# RL6955_IP_SVD register map
Vendor: Realtek
Registers are 32-bit, read-write, reset 0x0 unless marked. A register's access mark holds for its fields unless they carry their own. Offsets are from the block's base; [hi:lo] are bit positions; {n}, {i} and the like mark numbered series.

## DVP_REG
Base 0x41805000
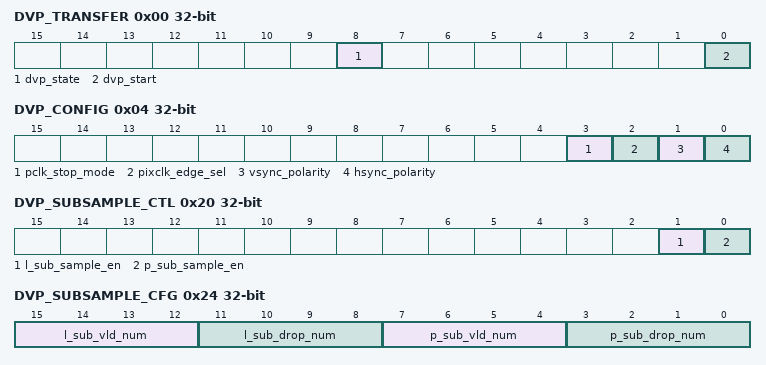
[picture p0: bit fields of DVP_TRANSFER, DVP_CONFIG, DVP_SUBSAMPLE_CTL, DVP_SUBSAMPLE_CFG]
0x00 DVP_TRANSFER access per field
  [8] dvp_state ro — 1: dvp enable 0: dvp disable
  [0] dvp_start wo — Start The transfer is launch if set this bit. When clear this bit, hardware will stop transfer after current image frame finish transfer. Dvp_start置1表示开流 停流方式可以选择配置immediate_stop或者是frame_stop来实现立即停流或者帧后停流.配置完immediate_stop或者是frame_stop后,dvp_state会自动拉低,拉低时间参考immediate_stop或者是frame_stop寄存器描述
0x04 DVP_CONFIG
  [3] pclk_stop_mode — PCLK Stop mode. Used when sensor uses HSYNC/VSYNC to perform gating on pclk, or pclk_stop_en open 0: normal 1: sensor pixclk stop mode
  [2] pixclk_edge_sel — Pixel clock sample edge. 0: falling edge, 1: rising edge.
  [1] vsync_polarity — Vsync polarity 0: active low, 1: active high.
  [0] hsync_polarity — Hsync polarity 0: active low, 1: active high.
0x0C DVP_CROP_START_X
  [12:0] dmy_pix_num — YUV path Unit: Bytes. This field indicates the number of dummy data before the valid data output. Hardware must bypass these dummy data and not sample the dummy data. yuv422 format config value is a multiple of 4 Eg: For YUV422 format, each pixel is represented by 2 bytes. Therefore, setting this field to 8 means skipping 4 pixels In formats like YUYV, YVYU, UYVY, and VYUY, data streams from the sensor to the DVP with each two pixels sharing the same UV components. Since each pair requires 2 pixels of 16bpp, it amounts to a total of 4 bytes. Therefore, operations involving this data should be done in multiples of 4 bytes. 用于crop丢掉数据
0x10 DVP_CROP_START_Y
  [11:0] dmy_line_num — YUV path This field indicates the number of dummy line before the valid line output. Hardware must bypass these dummy lines and not sample the dummy line data. 用于crop丢掉数据
0x14 DVP_WIDTH
  [12:0] pix_num_pre — YUV path Unit:bytes HORIZON_NUM10:0. This field indicates the number of valid data per line. yuv422 format config value is a multiple of 4 Eg: For YUV422 format, each pixel is represented by 2 bytes. Therefore, setting this field to 8 means reserved 4 pixels 用于crop选取有效数据,选取后的数据送往sub sample
0x18 DVP_HEIGHT
  [11:0] line_num_pre — YUV path VERTICAL_NUM10:0. This field indicates the number of valid line per frame. 用于crop选取有效数据,选取后的数据送往sub sample
0x1C DVP_FRAME_CNT ro
  [7:0] frame_num — Frame_cnt 7:0. This field is used to count the number of active Vsync from RealTimeImage transfer start. If the RealTimeImage transfer stop, the value of this register do not change. As soon as trigger RealTimeImage transfer, reset the value of thi register and restart to count.
0x20 DVP_SUBSAMPLE_CTL
  [1] l_sub_sample_en — YUV path Vertical (Line) Sub Sample control. 0: not sub sample, 1: sub sample.
  [0] p_sub_sample_en — YUV path Horizontal (Pixel) Sub sample control. 0: not sub sample, 1: sub sample.
0x24 DVP_SUBSAMPLE_CFG
  [15:12] l_sub_vld_num — YUV path Vertical Sub sample valid line number. 1-15:有效的line num是1-15 0:有效的line num是16
  [11:8] l_sub_drop_num — YUV path Vertical Sub sample invalid line number. 1-15:丢掉的line num是1-15 0:丢掉的line num是16
  [7:4] p_sub_vld_num — YUV path Horizontal (Pixel) Sub sample valid pixel number. yuv422 format config value: 4: vld 4 byte 8: vld 8 byte 12: vld 12 byte 0: vld 16 byte
  [3:0] p_sub_drop_num — YUV path Horizontal (Line) Sub sample invalid pixel number. yuv422 format config value: 4: drop 4 byte 8: drop 8 byte 12: drop 12 byte 0: drop 16 byte
0x28 DVP_FRMAE_VLD_CTL
  [3:0] frame_vld_num — FRAME_VALID_NUM 4'b0: all frame are valid otherwise: one frame valid in every (FRAME_VALID_NUM + 1 ) frames
0x2C DVP_YUV_TRANSFER
  [1:0] image_format — yuv422 sensor in format 2'b00: YUYV YUYV 2'b01: YVYU YVYU 2'b10: UYVY UYVY 2'b11: VYUY VYUY
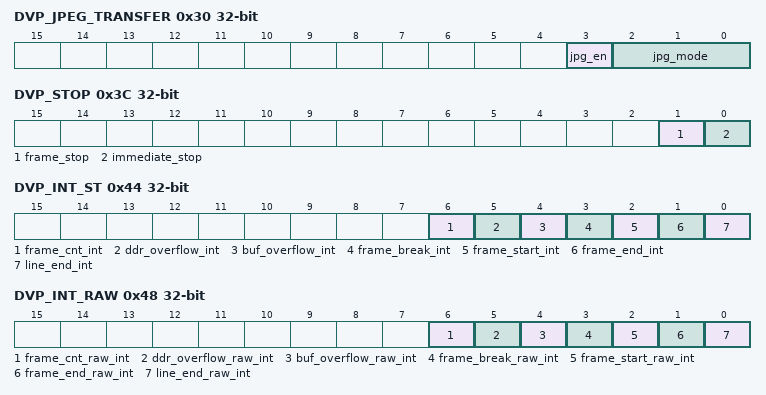
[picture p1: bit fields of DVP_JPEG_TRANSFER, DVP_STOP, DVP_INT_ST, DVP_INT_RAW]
0x30 DVP_JPEG_TRANSFER
  [3] jpg_en — DVP JPEG MODE EN 1: Enable DVP JPEG 0: Disable DVP JPEG
  [2:0] jpg_mode — DVP JPEG Mode 3'b000:Valid mode Use VSYNC as the frame synchronization signal and HSYNC as the horizontal synchronization signal. There is no dummy data in the frame. Support VSYNC pulse or level timing 3'b001:Frame mode Use VSYNC as the frame synchronization signal and HSYNC as the horizontal synchronization signal. There is dummy data in the frame. The frame contains valid data length , and valid data length is at the beginning of each line. 3'b010:Frame mode Use VSYNC as the frame synchronization signal and HSYNC as the horizontal synchronization signal. There is dummy data in the frame. The frame contains valid data length , and valid data length is at the end of each line. 3'b011:Frame mode Use VSYNC as the frame synchronization signal and HSYNC as the horizontal synchronization signal. There is dummy data in the frame. The frame does not contains valid data length. 3'b100:Use HSYNC as the frame synchronization signal,no dummy data
0x34 DVP_PCLK_GATING_CTL
  [0] pclk_gating_en — PCLK_GATING_EN 用于PCLK被VSYNC/HSYNC gating的情况,配合pclk_stop_mode使用,当pclk_gating_en置1时,pclk_stop_mode也要置1
0x38 DVP_PAD_CTL
  [1:0] pix_bit_swp — pixel bit switch 2'b01: pad[9:0]={bit7,bit6,bit5,bit4,bit3,bit2,bit1,bit0,2'd0} 2'b10: pad[9:0]={2'd0,bit0,bit1,bit2,bit3,bit4,bit5,bit6,bit7} 2'b00&2'b11: pad[9:0]={2'd0,bit7,bit6,bit5,bit4,bit3,bit2,bit1,bit0} YUV422 & JPG stream only 1 byte data valid in one PCLK cycle
0x3C DVP_STOP wo
  [1] frame_stop — The stop will not be triggered untill the current frame ends 当前帧结束以后停流(帧已经发送到psram中),下一帧不接收,当前帧结束以后会拉低dvp_state
  [0] immediate_stop — If set this bit, hardware will stop transfer and return idle state immediately. Hardware will auto clear this bit. 立即停流,同时拉低dvp_state.dma里存储的outstanding data依旧会发送出来,防止卡死platform
0x40 DVP_JPG_FRAME_LENGTH ro
  [21:0] jpg_frame_length — jpg frame size
0x44 DVP_INT_ST ro
  [6] frame_cnt_int — all frame buffer are fulled frames , and DVP will not to receive frames in time.then gen overflow int, need to check and clear frame status done register
  [5] ddr_overflow_int — ddr_overflow_int Only for frame buffer mode The allocated psram/ddr capacith is less than one frame
  [4] buf_overflow_int — dma buffer overflow int DMA needs to cache a certain amount of data before sending data to psram/ddr. The cached data is placed in buffer(memory), If there is too much cache and it is not sent, it means overflow
  [3] frame_break_int — frame_break_int yuv422 mode, The pixel count is internally compared with the configured frame size(ddr_len) pixel count是经过sub sample后的数据进行计算,这时的数据会送入缓存的buffer,等待传入psram. pixel count会与ddr_len进行比对,当pixel count小于ddr_len时会触发中断. 情况1:ddr len等于frame size, 当前帧破图,需要丢掉 情况2:ddr_len大于frame size,该中断没有参考意义 情况3: ddr_len小于frame size,可以通过ddr_overflow_int得知信息,需要及时调整ddr_len,使其满足frame_size jpg mode, The pixel will be counted internally, and for jpg timing with valid data length, it will be compared with the data length
  [2] frame_start_int — frame_start_int indicating that DVP is receiving a frame of image from sensor both yuv fb and jpeg 帧开始中断,这时dma已经准备发送图片
  [1] frame_end_int — frame_end_int both yuv fb and jpeg indicating that DVP has transfered one frame of image to memory
  [0] line_end_int — line_end_int Only for YUV path indicates that the image has been transferred to the configured number of lines(interrupt_line_num). 计算的是dma向psram中传输的line num
0x48 DVP_INT_RAW ro
  [6] frame_cnt_raw_int — frame buffer cnt overflow raw int, need to clear frame status done
  [5] ddr_overflow_raw_int — ddr_overflow_raw_int ddr/psram中断,通过所配置的ddr_len进行判断,模块内部会对传输的burst_length进行计数,当计数大于ddr_len时会触发中断
  [4] buf_overflow_raw_int — buf_overflow_raw_int dma缓存buffer中断,dma会缓存发往ddr/psram的数据,当满足一笔burst时dma会发起请求.当请求一直得不到回应同时缓存buffer溢出时会触发中断.
  [3] frame_break_raw_int
  [2] frame_start_raw_int
  [1] frame_end_raw_int
  [0] line_end_raw_int
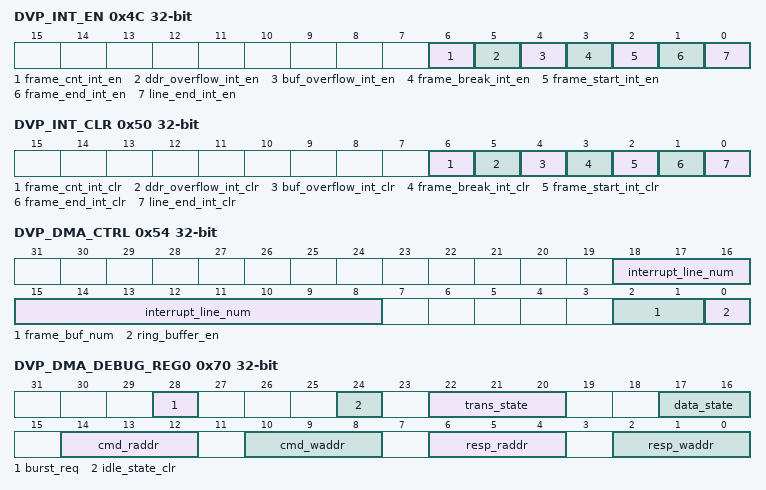
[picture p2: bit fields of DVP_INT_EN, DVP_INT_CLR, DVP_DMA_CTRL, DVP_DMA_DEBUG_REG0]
0x4C DVP_INT_EN
  [6] frame_cnt_int_en, [5] ddr_overflow_int_en, [4] buf_overflow_int_en, [3] frame_break_int_en, [2] frame_start_int_en, [1] frame_end_int_en, [0] line_end_int_en
0x50 DVP_INT_CLR wo
  [6] frame_cnt_int_clr, [5] ddr_overflow_int_clr, [4] buf_overflow_int_clr, [3] frame_break_int_clr, [2] frame_start_int_clr, [1] frame_end_int_clr, [0] line_end_int_clr
0x54 DVP_DMA_CTRL
  [18:8] interrupt_line_num — interrupt line num, for gen specific line end int
  [2:1] frame_buf_num — number of used frame buffer used number = frame_buf_num + 1
  [0] ring_buffer_en — ring buffer mode enable ring buffer mode只在yuv mode下使用,因为jpg数据流没有行的概念,DVP与MJPEG无法进行交互.
0x58 DVP_FRAME_ADDR0
  [31:2] frame_addr0 — frame buffer 0 start addr, 4 byte align ring buffer start addr,4 byte align
{0x58+4i} DVP_FRAME_ADDR{i} (i=1..3)
  [31:2] frame_addr{i} — frame buffer {i} start addr, 4 byte align
0x68 DVP_DDR_LEN
  [23:2] ddr_len — ddr length, 4 byte align frame_buffer mode is frame size ring buffer mode is ring buffer szie The size of the slave space written by dma, here refers to the size of the psram allocated YUV MODE ddr_len配置大小应为frame size JPG MODE jpg数据流大小不固定,这里需要保险期间配置大一些,配置大小需要计算jpg的压缩比例和压缩前的图片大小,建议值是压缩比*sensor分辨率 RING BUFFER,FRAME BUFFE共用寄存器 切换方式通过ring_buffer_en进行切换. ring_buffer_en为1时,ddr_len表示ring buffer length ring_buffer_en为0时,ddr_len表示frame buffer length
0x70 DVP_DMA_DEBUG_REG0 ro
  [28] burst_req, [24] idle_state_clr, [22:20] trans_state, [17:16] data_state, [14:12] cmd_raddr, [10:8] cmd_waddr, [6:4] resp_raddr, [2:0] resp_waddr
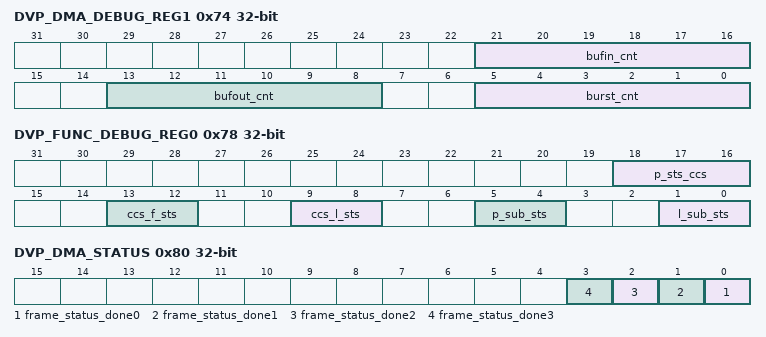
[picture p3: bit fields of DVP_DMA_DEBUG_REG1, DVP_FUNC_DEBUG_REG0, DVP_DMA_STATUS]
0x74 DVP_DMA_DEBUG_REG1 ro
  [21:16] bufin_cnt, [13:8] bufout_cnt, [5:0] burst_cnt
0x78 DVP_FUNC_DEBUG_REG0 ro
  [18:16] p_sts_ccs, [13:12] ccs_f_sts, [9:8] ccs_l_sts, [5:4] p_sub_sts, [1:0] l_sub_sts
0x80 DVP_DMA_STATUS
  [n] frame_status_done{n} (n=0..3) — frame buffer {n} done 1: frame buffer full 0: frame buffer empty or receiving frame 当frame_end_int中断拉高时,需要读取该寄存器地址,通过bit位置1的位置来得知哪一块frame buffer经过接收完一帧数据.然后software及时去相应的frame buffer取数据,取完数据以后将该bit位写1置0
